AUTOSAR XML (schema 00049)
package /ota/software_componenets
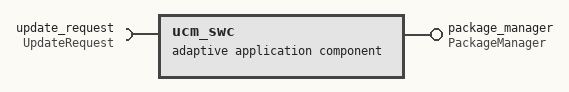
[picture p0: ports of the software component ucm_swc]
  adaptive application sw component type ucm_swc
    provide port package_manager: provided-interface=PackageManager
    require port update_request: required-interface=UpdateRequest
  adaptive application sw component type ota_swc
    require port package_manager: required-interface=PackageManager
  adaptive application sw component type sm_swc
    provide port update_request: provided-interface=UpdateRequest
